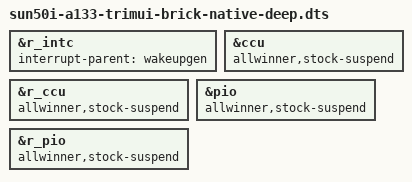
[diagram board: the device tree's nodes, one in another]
// SPDX-License-Identifier: (GPL-2.0+ OR MIT)
/*
 * Native SCP deep-suspend wake routing. Stock handles the PMIC NMI through
 * proprietary power-management code; Linux instead needs its parent SPI in
 * the wakeupgen hierarchy so irq_set_wake() reaches the same SCP service.
 */

#include "sun50i-a133-trimui-brick-native-wake.dts"
#include "sun50i-a133-stock-psci-idle.dtsi"

/* Preserve ordinary GIC delivery while forwarding NMI wake votes to SCP. */
&r_intc {
	interrupt-parent = <&wakeupgen>;
};

/* Reconstruct the context that the SCP-powered deep state does not retain. */
&ccu {
	allwinner,stock-suspend;
};

&r_ccu {
	allwinner,stock-suspend;
};

&pio {
	allwinner,stock-suspend;
};

&r_pio {
	allwinner,stock-suspend;
};
